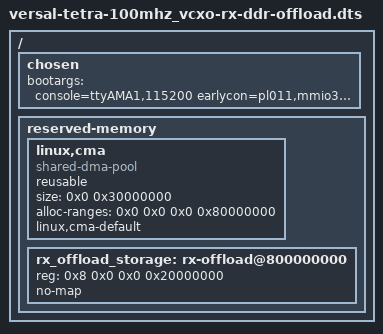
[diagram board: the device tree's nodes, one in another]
// SPDX-License-Identifier: GPL-2.0
/*
 * dts file for Xilinx Versal Tetra, RX data offload storage in LPDDR4
 *
 * HDL: make ADC_DO_MEM_TYPE=1
 *
 * With 12-bit samples (RX_JESD_NP=12) the offload stores them packed and the
 * DMA receives them unpacked, 16 bits each: the RX offload transfer_length
 * counts packed bytes, 3/4 of the DMA buffer size, and the DMA buffer size
 * must be a multiple of 256 bytes.
 *
 * (C) Copyright 2026, Analog Devices Inc.
 */

#include "versal-tetra-100mhz_vcxo.dts"

/ {
	chosen {
		/* One block can hold a full capture, 512 MiB unpacked to 683 MiB */
		bootargs = "console=ttyAMA1,115200 earlycon=pl011,mmio32,0xFF010000,115200n8 root=/dev/mmcblk0p2 rw rootfstype=ext4 rootwait industrialio_buffer_dma.max_block_size=805306368";
	};

	reserved-memory {
		#address-cells = <2>;
		#size-cells = <2>;
		ranges;

		/*
		 * The RX DMA only reaches DDR_LOW0, so the capture buffer must
		 * come from the lower 2 GB. 768 MiB holds a full capture.
		 */
		linux,cma {
			compatible = "shared-dma-pool";
			reusable;
			size = <0x0 0x30000000>;
			alloc-ranges = <0x0 0x0 0x0 0x80000000>;
			linux,cma-default;
		};

		/*
		 * RX data offload storage, written by the PL; kept out of Linux
		 * even if the bootloader reports the whole of DDR_LOW1
		 */
		rx_offload_storage: rx-offload@800000000 {
			reg = <0x8 0x0 0x0 0x20000000>;
			no-map;
		};
	};
};
